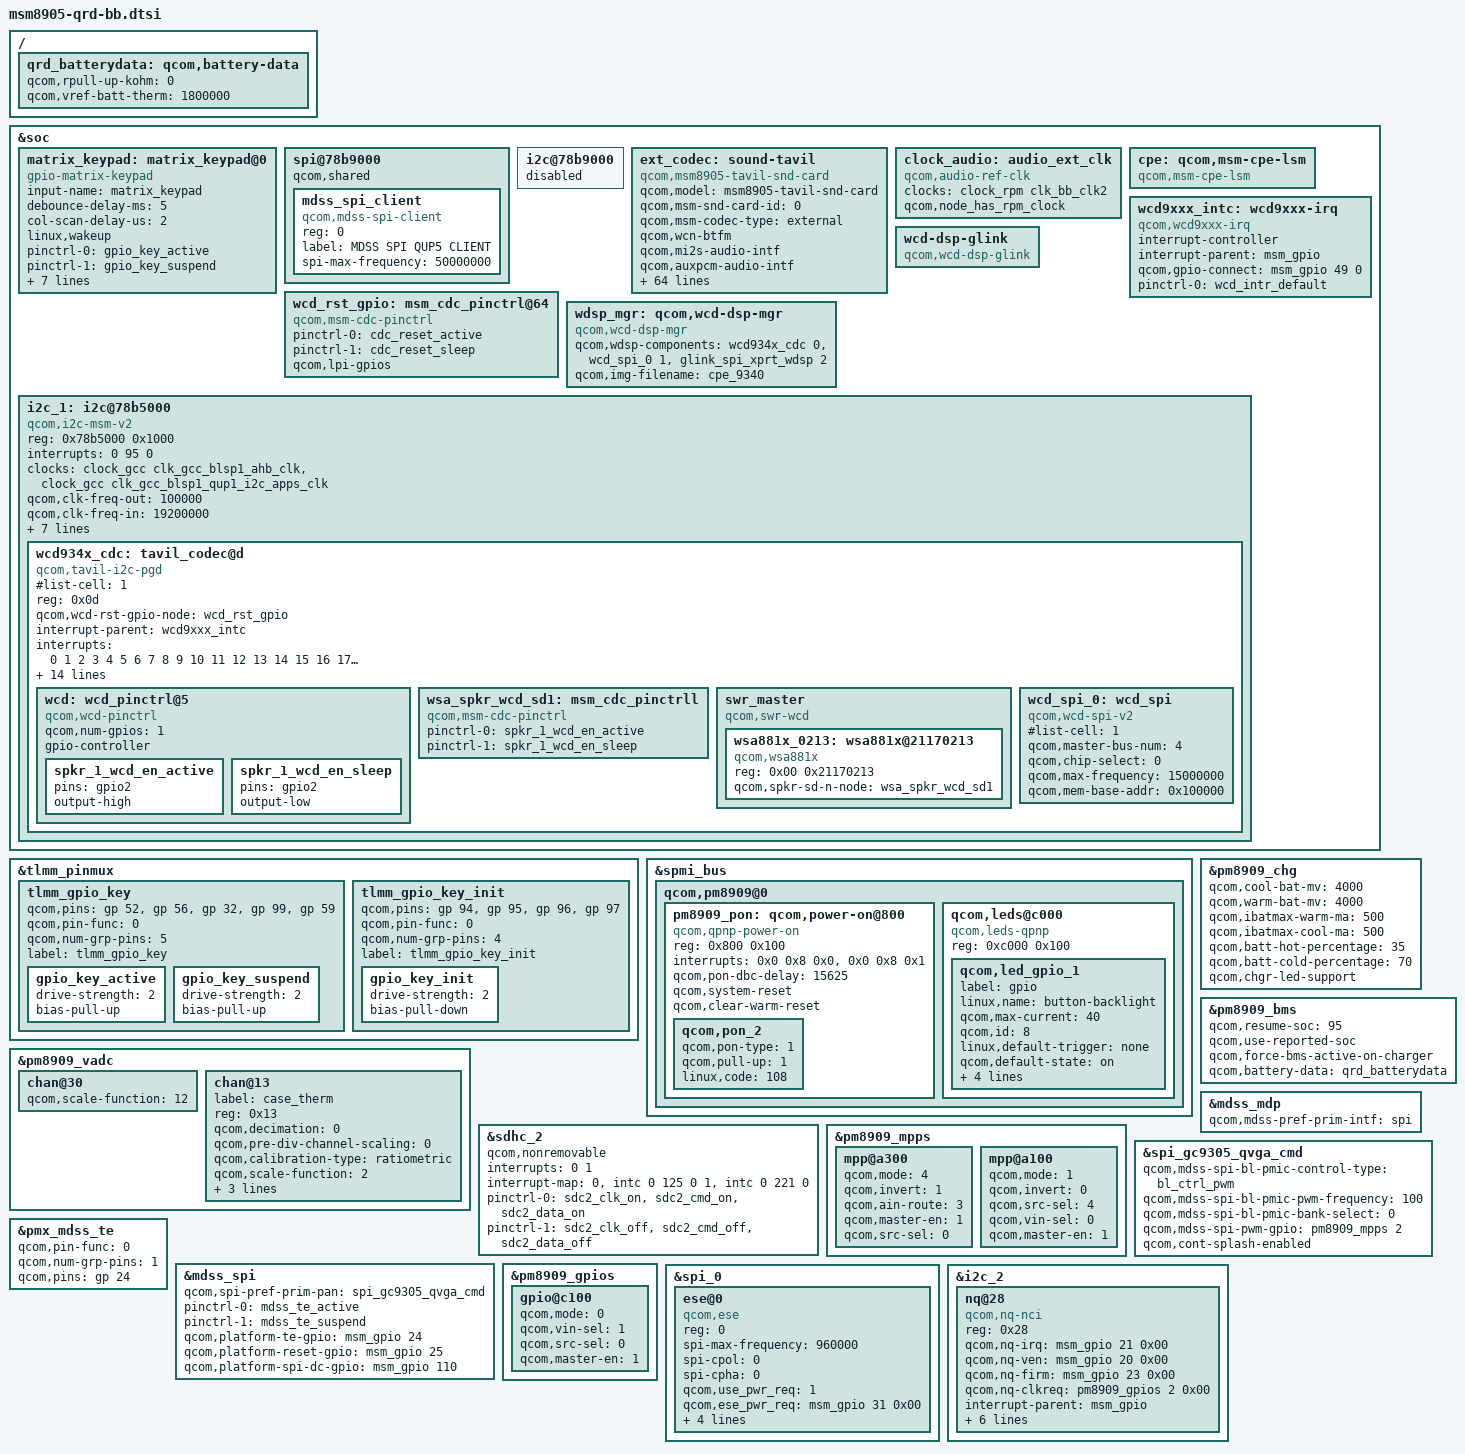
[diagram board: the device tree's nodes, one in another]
/* Copyright (c) 2017-2018 The Linux Foundation. All rights reserved.
 *
 * This program is free software; you can redistribute it and/or modify
 * it under the terms of the GNU General Public License version 2 and
 * only version 2 as published by the Free Software Foundation.
 *
 * This program is distributed in the hope that it will be useful,
 * but WITHOUT ANY WARRANTY; without even the implied warranty of
 * MERCHANTABILITY or FITNESS FOR A PARTICULAR PURPOSE.  See the
 * GNU General Public License for more details.
 */

#include "msm8909-qrd-bb.dtsi"
#include "msm8905.dtsi"
#include "msm8905-camera-sensor-bb.dtsi"

&soc {
	matrix_keypad: matrix_keypad@0 {
		       compatible = "gpio-matrix-keypad";
		       input-name = "matrix_keypad";
		       debounce-delay-ms = <5>;
		       col-scan-delay-us = <2>;
		       linux,wakeup;
		       pinctrl-names = "tlmm_gpio_key_active","tlmm_gpio_key_suspend","tlmm_gpio_key_init";
		       pinctrl-0 = <&gpio_key_active>;
		       pinctrl-1 = <&gpio_key_suspend>;
                       pinctrl-2 = <&gpio_key_init>;

		       row-gpios = <&msm_gpio 97 0
			       &msm_gpio 96 0
			       &msm_gpio 95 0
			       &msm_gpio 94 0>;

		       col-gpios = <&msm_gpio 52 0
			       &msm_gpio 56 0
			       &msm_gpio 32 0
			       &msm_gpio 99 0
			       &msm_gpio 59 0>;
		       linux,keymap = <0x00000160      /* (0,0) KEY_DIAL -->KEY_CENTER 352*/
			       0x00010007      /* (1,0) KEY_3 --> KEY_6*/
			       0x00020067      /* (2,0) KEY_6 --> KEY_UP*/
			       0x00030006      /* (3,0) KEY_9 --> KEY_5*/
			       0x00040069      /* (4,0) KEY_NUMERIC_POUND -> KEY_LEFT*/

			       0x01000004      /* (0,1) KEY_LEFT -->KEY_3*/
			       0x0101020b      /* (1,1) KEY_2 --> KEY_NUMERIC_POUND*/
			       0x0102008b       /* (2,1) KEY_5 --> KEY_MENU*/
			       0x01030008      /* (3,1) KEY_8 --> KEY_7*/
			       0x01040005      /* (4,1) KEY_0 -->KEY_4*/

			       0x0200006c      /* (0,2) KEY_MENU -->KEY_DOWN*/
			       0x0201020a      /* (1,2) KEY_1 --> KEY_NUMERIC_STAR*/
			       0x0202006a      /* (2,2) KEY_4 --> KEY_RIGHT*/
			       0x0203000a      /* (3,2) KEY_7 -- KEY_9*/
			       0x020400e7      /* (4,2) KEY_NUMERIC_STAR -->KEY_DIAL*/

			       0x03000003      /* (0,3) KEY_OK -->KEY_2*/
			       0x03010009      /* (1,3) KEY_RIGHT --> KEY_8*/
			       0x0302009e      /* (2,3)  --> KEY_BACK*/
			       0x0303000b      /* (3,3) KEY_BACK -->KEY_0*/
				   0x03040002    /* (4,3)  --> KEY_1*/
			       >;

	       };

};

&tlmm_pinmux {
	tlmm_gpio_key {
		qcom,pins = <&gp 52>, <&gp 56>, <&gp 32>, <&gp 99>, <&gp 59>;
		qcom,pin-func = <0>;
		qcom,num-grp-pins = <5>;
		label = "tlmm_gpio_key";
	gpio_key_active: gpio_key_active {
			 drive-strength = <2>;
			 bias-pull-up;
		 };
	gpio_key_suspend: gpio_key_suspend {
			  drive-strength = <2>;
			  bias-pull-up;
		  };
	};

	tlmm_gpio_key_init {
		qcom,pins = <&gp 94>, <&gp 95>, <&gp 96>, <&gp 97>;
		qcom,pin-func = <0>;
		qcom,num-grp-pins = <4>;
		label = "tlmm_gpio_key_init";
		gpio_key_init: gpio_key_init {
			 drive-strength = <2>;
			 bias-pull-down;
		 };
	 };
};

&spmi_bus {
	qcom,pm8909@0 {
		pm8909_pon: qcom,power-on@800 {
		    compatible = "qcom,qpnp-power-on";
		    reg = <0x800 0x100>;
		    interrupts = <0x0 0x8 0x0>,
			       <0x0 0x8 0x1>;
		    interrupt-names = "kpdpwr", "resin";
		    qcom,pon-dbc-delay = <15625>;
		    qcom,system-reset;
		    qcom,clear-warm-reset;

		    qcom,pon_2 {
			    qcom,pon-type = <1>;
			    qcom,pull-up = <1>;
			    linux,code = <108>;
		    };
		};
	};
};
&pm8909_vadc {
	chan@30 {
		qcom,scale-function = <6>;
	};
};

&spmi_bus {
	qcom,pm8909@0 {
		qcom,leds@c000 {
			compatible = "qcom,leds-qpnp";
			reg = <0xc000 0x100>;
			status = "okay";
			qcom,led_gpio_1 {
				label = "gpio";
				linux,name = "button-backlight";
				qcom,max-current = <40>;
				qcom,id = <8>;
				linux,default-trigger = "none";
				qcom,default-state = "on";
				qcom,turn-off-delay-ms = <1000>;
				qcom,source-sel = <1>;
				qcom,mode-ctrl = <0x10>;
				qcom,vin-ctrl = <0x02>;
			};
		};
	};
};

&pm8909_chg {
	qcom,cool-bat-mv = <4000>;
	qcom,warm-bat-mv = <4000>;
	qcom,ibatmax-warm-ma = <500>;
	qcom,ibatmax-cool-ma = <500>;
	qcom,batt-hot-percentage = <35>;
	qcom,batt-cold-percentage = <70>;
	qcom,chgr-led-support;
	status = "okay";
};

/ {
	qrd_batterydata: qcom,battery-data {
		qcom,rpull-up-kohm = <0>;
		qcom,vref-batt-therm = <1800000>;

		#include "batterydata-qrd-skub-4v2-2000mah.dtsi"
	};
};

&pm8909_bms {
	status = "okay";
	qcom,resume-soc = <95>;
	qcom,use-reported-soc;
	qcom,force-bms-active-on-charger;
	qcom,battery-data = <&qrd_batterydata>;
};

&sdhc_2 {
        qcom,nonremovable;
        interrupts = <0 1>;
        interrupt-map = <0 &intc 0 125 0
                1 &intc 0 221 0>;
        interrupt-names = "hc_irq", "pwr_irq";
        /delete-property/ cd-gpios;
	pinctrl-names = "active", "sleep";
	pinctrl-0 = <&sdc2_clk_on &sdc2_cmd_on &sdc2_data_on>;
	pinctrl-1 = <&sdc2_clk_off &sdc2_cmd_off &sdc2_data_off>;
};

&pm8909_mpps {
	mpp@a300 { /* MPP 4 */
		 /* CASE_THERM config */
		 qcom,mode = <4>; /* AIN input */
		 qcom,invert = <1>; /* Enable MPP */
		 qcom,ain-route = <3>; /* AMUX 8 */
		 qcom,master-en = <1>;
		 qcom,src-sel = <0>; /* Function constant */
	};
};

&pm8909_vadc {
	chan@30 {
		qcom,scale-function = <12>;
	};

	chan@13 {
		label = "case_therm";
		reg = <0x13>;
		qcom,decimation = <0>;
		qcom,pre-div-channel-scaling = <0>;
		qcom,calibration-type = "ratiometric";
		qcom,scale-function = <2>;
		qcom,hw-settle-time = <2>;
		qcom,fast-avg-setup = <0>;
		qcom,vadc-thermal-node;
	};
};

&soc {
	spi@78b9000 { /* BLSP1 QUP5 */
		status = "okay";
		qcom,shared;
		mdss_spi_client {
			reg = <0>;
			compatible = "qcom,mdss-spi-client";
			label = "MDSS SPI QUP5 CLIENT";
			spi-max-frequency = <50000000>;
		};
	};

	i2c@78b9000 {/* BLSP1 QUP5 */
		status = "disabled";
	};

	ext_codec: sound-tavil {
		status = "okay";
		compatible = "qcom,msm8905-tavil-snd-card";
		qcom,model = "msm8905-tavil-snd-card";
                qcom,msm-snd-card-id = <0>;
		qcom,msm-codec-type = "external";
		qcom,wcn-btfm;
		qcom,mi2s-audio-intf;
		qcom,auxpcm-audio-intf;
		qcom,ext-disp-audio-rx;
		qcom,afe-rxtx-lb;
		qcom,msm-ext-pa = "quaternary";
		/* Only 4 MI2S are connected all are set to master to be check*/
		qcom,msm-mi2s-master = <1>, <1>, <1>, <1>;
		qcom,audio-routing =
			"AIF4 VI", "MCLK",
			"RX_BIAS", "MCLK",
			"MADINPUT", "MCLK",
			"hifi amp", "LINEOUT1",
			"hifi amp", "LINEOUT2",
			"AMIC1", "MIC BIAS1",
			"MIC BIAS1", "Handset Mic",
			"AMIC2", "MIC BIAS2",
			"MIC BIAS2", "Headset Mic",
			"AMIC3", "MIC BIAS3",
			"MIC BIAS3", "Secondary Mic",
			"MIC BIAS2", "ANCRight Headset Mic",
			"AMIC4", "MIC BIAS2",
			"MIC BIAS2", "ANCLeft Headset Mic",
			"AMIC5", "MIC BIAS3",
			"MIC BIAS3", "Handset Mic",
			"DMIC0", "MIC BIAS1",
			"MIC BIAS1", "Digital Mic0",
			"DMIC1", "MIC BIAS1",
			"MIC BIAS1", "Digital Mic1",
			"DMIC2", "MIC BIAS3",
			"MIC BIAS3", "Digital Mic2",
			"DMIC3", "MIC BIAS3",
			"MIC BIAS3", "Digital Mic3",
			"DMIC4", "MIC BIAS4",
			"MIC BIAS4", "Digital Mic4",
			"DMIC5", "MIC BIAS4",
			"MIC BIAS4", "Digital Mic5",
			"SpkrLeft IN", "SPK1 OUT",
			"SpkrRight IN", "SPK2 OUT";
		asoc-platform = <&pcm0>, <&pcm1>, <&voip>, <&voice>,
				<&loopback>, <&compress>, <&hostless>,
				<&afe>, <&lsm>, <&routing>, <&lpa>;
		asoc-platform-names = "msm-pcm-dsp.0", "msm-pcm-dsp.1",
			"msm-voip-dsp", "msm-pcm-voice", "msm-pcm-loopback",
			"msm-compress-dsp", "msm-pcm-hostless", "msm-pcm-afe",
                        "msm-lsm-client", "msm-pcm-routing", "msm-pcm-lpa";
		asoc-cpu = <&dai_pri_auxpcm>, <&dai_hdmi>,
			<&dai_mi2s0>, <&dai_mi2s1>, <&dai_mi2s2>, <&dai_mi2s3>,
			<&sb_0_rx>, <&sb_0_tx>, <&sb_1_rx>, <&sb_1_tx>,
			<&sb_3_rx>, <&sb_3_tx>, <&sb_4_rx>, <&sb_4_tx>,
			<&bt_sco_rx>, <&bt_sco_tx>,
			<&bt_a2dp_rx>, <&int_fm_rx>, <&int_fm_tx>,
			<&afe_pcm_rx>, <&afe_pcm_tx>, <&afe_proxy_rx>, <&afe_proxy_tx>,
			<&incall_record_rx>, <&incall_record_tx>, <&incall_music_rx>,
			<&incall_music_2_rx>,<&afe_loopback_tx> ;
		asoc-cpu-names = "msm-dai-q6-auxpcm.1", "msm-dai-q6-hdmi.8",
			"msm-dai-q6-mi2s.0", "msm-dai-q6-mi2s.1",
			"msm-dai-q6-mi2s.2", "msm-dai-q6-mi2s.3",
			"msm-dai-q6-dev.16384",	"msm-dai-q6-dev.16385",
			"msm-dai-q6-dev.16386", "msm-dai-q6-dev.16387",
			"msm-dai-q6-dev.16390", "msm-dai-q6-dev.16391",
			"msm-dai-q6-dev.16392",	"msm-dai-q6-dev.16393",
			"msm-dai-q6-dev.12288", "msm-dai-q6-dev.12289",
			"msm-dai-q6-dev.12290",
			"msm-dai-q6-dev.12292", "msm-dai-q6-dev.12293",
			"msm-dai-q6-dev.224", "msm-dai-q6-dev.225",
			"msm-dai-q6-dev.241", "msm-dai-q6-dev.240",
			"msm-dai-q6-dev.32771", "msm-dai-q6-dev.32772",
			"msm-dai-q6-dev.32773", "msm-dai-q6-dev.32770",
			"msm-dai-q6-dev.24577";
		qcom,msm-mbhc-hphl-swh = <1>;
		qcom,msm-mbhc-gnd-swh = <1>;
		qcom,msm-mclk-freq = <9600000>;
		asoc-codec = <&stub_codec>;/*, <&ext_disp_audio_codec>;*/
		asoc-codec-names = "msm-stub-codec.1"; /*msm-ext-disp-audio-codec-rx*/
                qcom,msm-gpios =
                        "quat_i2s";
		pinctrl-names = "cdc_lines_quat_ext_sus",
				"cdc_lines_quat_ext_act";
		pinctrl-0 = <&cdc_ext_tlmm_sus>;
		pinctrl-1 = <&cdc_ext_tlmm_act>;
                qcom,max-aux-codec = <1>;
                qcom,aux-codec = "wsa881x.21170213";
                qcom,aux-codec-prefix = "SpkrLeft";
	};

	clock_audio: audio_ext_clk {
		status = "okay";
                compatible = "qcom,audio-ref-clk";
		clock-names = "osr_clk";
		clocks = <&clock_rpm clk_bb_clk2>;
		qcom,node_has_rpm_clock;
		#clock-cells = <1>;
	};

	cpe: qcom,msm-cpe-lsm {
                compatible = "qcom,msm-cpe-lsm";
        };
	wcd9xxx_intc: wcd9xxx-irq {
		status = "okay";
		compatible = "qcom,wcd9xxx-irq";
		interrupt-controller;
		#interrupt-cells = <1>;
		interrupt-parent = <&msm_gpio>;
		qcom,gpio-connect = <&msm_gpio 49 0>;
		pinctrl-names = "default";
		pinctrl-0 = <&wcd_intr_default>;
	};


	wcd_rst_gpio: msm_cdc_pinctrl@64 {
		status = "okay";
		compatible = "qcom,msm-cdc-pinctrl";
		pinctrl-names = "aud_active", "aud_sleep";
		pinctrl-0 = <&cdc_reset_active>;
		pinctrl-1 = <&cdc_reset_sleep>;
		qcom,lpi-gpios;
	};
	wdsp_mgr: qcom,wcd-dsp-mgr {
		compatible = "qcom,wcd-dsp-mgr";
		qcom,wdsp-components =  <&wcd934x_cdc 0>,
					<&wcd_spi_0 1>,
					<&glink_spi_xprt_wdsp 2>;
					qcom,img-filename = "cpe_9340";
	};

	wcd-dsp-glink {
		compatible = "qcom,wcd-dsp-glink";
	};

	i2c_1: i2c@78b5000 { /* BLSP1 QUP1 */
		compatible = "qcom,i2c-msm-v2";
		#address-cells = <1>;
		#size-cells = <0>;
		reg-names = "qup_phys_addr";
		reg = <0x78b5000 0x1000>;
		interrupt-names = "qup_irq";
		interrupts = <0 95 0>;
		clocks = <&clock_gcc clk_gcc_blsp1_ahb_clk>,
			<&clock_gcc clk_gcc_blsp1_qup1_i2c_apps_clk>;
		clock-names = "iface_clk", "core_clk";
		qcom,clk-freq-out = <100000>;
		qcom,clk-freq-in  = <19200000>;
		pinctrl-names = "i2c_active", "i2c_sleep";
		pinctrl-0 = <&i2c_1_active>;
		pinctrl-1 = <&i2c_1_sleep>;
		qcom,noise-rjct-scl = <0>;
		qcom,noise-rjct-sda = <0>;
		dmas = <&dma_blsp1 4 64 0x20000020 0x20>,
			<&dma_blsp1 5  32 0x20000020 0x20>;
		dma-names = "tx", "rx";
		qcom,master-id = <86>;
		status = "ok";
		wcd934x_cdc: tavil_codec@d {
				#address-cells = <1>;
				#size-cells = <0>;
				#list-cell = <1>;
				compatible = "qcom,tavil-i2c-pgd";
				reg = <0x0d>;
				status = "ok";
				qcom,wcd-rst-gpio-node = <&wcd_rst_gpio>;
				interrupt-parent = <&wcd9xxx_intc>;
				interrupts = <0 1 2 3 4 5 6 7 8 9 10 11 12 13 14 15 16
						17 18 19 20 21 22 23 24 25 26 27 28 29
						30>;
				clock-names = "audio_tx_mclk";
				clocks = <&clock_audio clk_bb_clk2>;
				pinctrl-names = "default";
				qcom,cdc-micbias1-mv = <1800>;
				qcom,cdc-micbias2-mv = <1800>;
				qcom,cdc-micbias3-mv = <1800>;
				qcom,cdc-micbias4-mv = <1800>;

				cdc-vdd-gpio-supply = <&pm8909_l15>;
				qcom,cdc-vdd-gpio-voltage = <1800000 1800000>;
				qcom,cdc-vdd-gpio-current = <650000>;
				qcom,cdc-static-supplies = "cdc-vdd-gpio";

				qcom,cdc-mclk-clk-rate = <9600000>;
				qcom,cdc-dmic-sample-rate = <4800000>;
				qcom,cdc-mad-dmic-rate = <600001>;
				qcom,cdc-ecpp-dmic-rate = <1200000>;

				qcom,wdsp-cmpnt-dev-name = "tavil_codec";

				wcd: wcd_pinctrl@5 {
					compatible = "qcom,wcd-pinctrl";
					qcom,num-gpios = <1>;
					gpio-controller;
					#gpio-cells = <2>;

					spkr_1_wcd_en_active: spkr_1_wcd_en_active {
						pins = "gpio2";
						output-high;
					};

					spkr_1_wcd_en_sleep: spkr_1_wcd_en_sleep {
						pins = "gpio2";
						output-low;
					};

				};
				wsa_spkr_wcd_sd1: msm_cdc_pinctrll {
					compatible = "qcom,msm-cdc-pinctrl";
					pinctrl-names = "aud_active", "aud_sleep";
					pinctrl-0 = <&spkr_1_wcd_en_active>;
					pinctrl-1 = <&spkr_1_wcd_en_sleep>;
				};
				swr_master {
					compatible = "qcom,swr-wcd";
					#address-cells = <2>;
					#size-cells = <0>;

					wsa881x_0213: wsa881x@21170213 {
						compatible = "qcom,wsa881x";
						reg = <0x00 0x21170213>;
						qcom,spkr-sd-n-node = <&wsa_spkr_wcd_sd1>;
					};

				};
				wcd_spi_0: wcd_spi {
					compatible = "qcom,wcd-spi-v2";
					#list-cell = <1>;
					qcom,master-bus-num = <4>;
					qcom,chip-select = <0>;
					qcom,max-frequency = <15000000>;
					qcom,mem-base-addr = <0x100000>;
				};
			};
	};
};

&pm8909_mpps {
	mpp@a100 { /* MPP 2 */
		/* Backlight PWM */
		qcom,mode = <1>;		/* Digital output */
		qcom,invert = <0>;		/* Disable invert */
		qcom,src-sel = <4>;		/* DTEST1 */
		qcom,vin-sel = <0>;		/* VPH_PWR */
		qcom,master-en = <1>;		/* Enable MPP */
	};
};

#include "spi-panel-gc9305-qvga-cmd.dtsi"
#include "spi-panel-holitech-gc9305-id-qvga-cmd.dtsi"

&mdss_mdp {
	qcom,mdss-pref-prim-intf = "spi";
};

&spi_gc9305_qvga_cmd {
	qcom,mdss-spi-bl-pmic-control-type = "bl_ctrl_pwm";
	qcom,mdss-spi-bl-pmic-pwm-frequency = <100>;
	qcom,mdss-spi-bl-pmic-bank-select = <0>;
	qcom,mdss-spi-pwm-gpio = <&pm8909_mpps 2 0>;
	qcom,cont-splash-enabled;
};

&pmx_mdss_te {
	qcom,pin-func = <0>;
	qcom,num-grp-pins = <1>;
	qcom,pins = <&gp 24>;
};

&mdss_spi {
	qcom,spi-pref-prim-pan = <&spi_gc9305_qvga_cmd>;
	pinctrl-names = "mdss_default", "mdss_sleep";
	pinctrl-0 = <&mdss_te_active>;
	pinctrl-1 = <&mdss_te_suspend>;

	qcom,platform-te-gpio = <&msm_gpio 24 0>;
	qcom,platform-reset-gpio = <&msm_gpio 25 0>;
	qcom,platform-spi-dc-gpio = <&msm_gpio 110 0>;
};

&pm8909_gpios {
        /* GPIO 2 (NFC_CLK_REQ) */
        gpio@c100 {
                qcom,mode = <0>;
                qcom,vin-sel = <1>;
                qcom,src-sel = <0>;
                qcom,master-en = <1>;
                status = "okay";
        };
};

&spi_0 {
	status = "okay";
	ese@0 {
		compatible = "qcom,ese";
		reg = <0>;
		spi-max-frequency = <960000>;
		spi-cpol = <0>;
		spi-cpha =<0>;
		/* if no pwr req this must be 0 else 1*/
		qcom,use_pwr_req = <1>;
		qcom,ese_pwr_req = <&msm_gpio 31 0x00>;
		/* if no intr req this must be 0 else 1*/
		qcom,use_interrupt = <0>;
		/*qcom,ese_intr = <&msm_gpio 35 0x00>;*/
		pinctrl-names = "ese_active", "ese_suspend";
		pinctrl-0 = <&ese_int_active &ese_disable_active>;
		pinctrl-1 = <&ese_int_suspend &ese_disable_suspend>;
	};
};

&i2c_2 {
        status = "okay";
        nq@28 {
                compatible = "qcom,nq-nci";
                reg = <0x28>;
                qcom,nq-irq = <&msm_gpio 21 0x00>;
                qcom,nq-ven = <&msm_gpio 20 0x00>;
                qcom,nq-firm = <&msm_gpio 23 0x00>;
                qcom,nq-clkreq = <&pm8909_gpios 2 0x00>;
                /*qcom,nq-esepwr = <&msm_gpio 31 0x00>;*/
                interrupt-parent = <&msm_gpio>;
                qcom,clk-src = "BBCLK2";
                interrupts = <21 0>;
                interrupt-names = "nfc_irq";
                pinctrl-names = "nfc_active", "nfc_suspend";
                pinctrl-0 = <&nfc_int_active &nfc_disable_active>;
                pinctrl-1 = <&nfc_int_suspend &nfc_disable_suspend>;
                clocks = <&clock_rpm clk_bb_clk2_pin>;
                clock-names = "ref_clk";
        };
};
